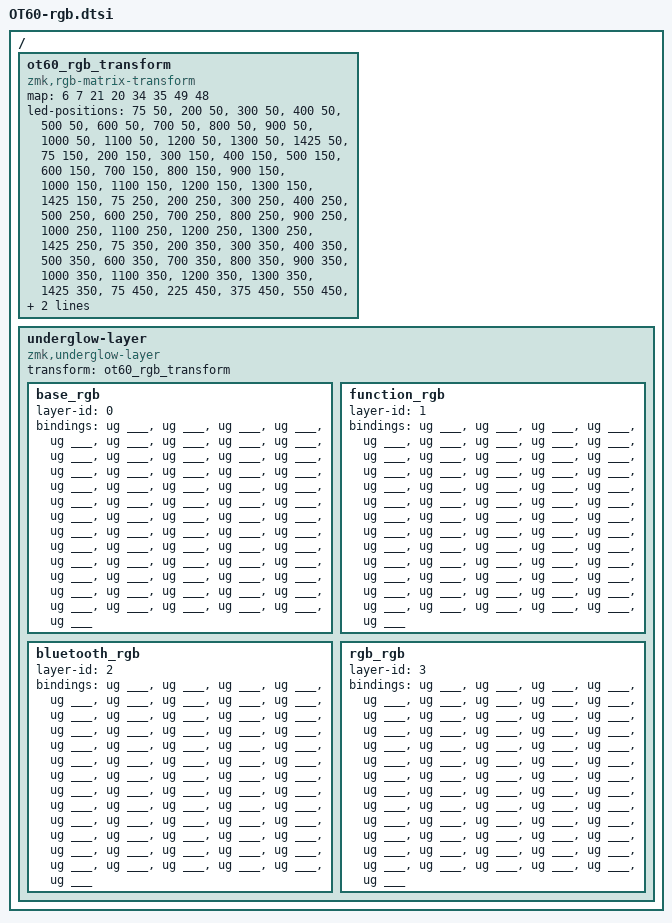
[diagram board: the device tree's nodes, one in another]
/* Copyright (c) 2026 Team PHDesign
 * SPDX-License-Identifier: MIT
 */
#include <dt-bindings/zmk/rgb_colors.h>

/ {
    ot60_rgb_transform: ot60_rgb_transform {
        compatible = "zmk,rgb-matrix-transform";
        // RGB1..RGB8 -> S7,S8,S22,S21,S35,S36,S50,S49 (PCB position export).
        map = <6 7 21 20 34 35 49 48>;
        led-positions = <75 50>
                      , <200 50>
                      , <300 50>
                      , <400 50>
                      , <500 50>
                      , <600 50>
                      , <700 50>
                      , <800 50>
                      , <900 50>
                      , <1000 50>
                      , <1100 50>
                      , <1200 50>
                      , <1300 50>
                      , <1425 50>
                      , <75 150>
                      , <200 150>
                      , <300 150>
                      , <400 150>
                      , <500 150>
                      , <600 150>
                      , <700 150>
                      , <800 150>
                      , <900 150>
                      , <1000 150>
                      , <1100 150>
                      , <1200 150>
                      , <1300 150>
                      , <1425 150>
                      , <75 250>
                      , <200 250>
                      , <300 250>
                      , <400 250>
                      , <500 250>
                      , <600 250>
                      , <700 250>
                      , <800 250>
                      , <900 250>
                      , <1000 250>
                      , <1100 250>
                      , <1200 250>
                      , <1300 250>
                      , <1425 250>
                      , <75 350>
                      , <200 350>
                      , <300 350>
                      , <400 350>
                      , <500 350>
                      , <600 350>
                      , <700 350>
                      , <800 350>
                      , <900 350>
                      , <1000 350>
                      , <1100 350>
                      , <1200 350>
                      , <1300 350>
                      , <1425 350>
                      , <75 450>
                      , <225 450>
                      , <375 450>
                      , <550 450>
                      , <750 450>
                      , <950 450>
                      , <1125 450>
                      , <1275 450>
                      , <1425 450>;
    };
    underglow-layer {
        compatible = "zmk,underglow-layer";
        transform = <&ot60_rgb_transform>;
        base_rgb {
            layer-id = <0>;
            bindings = <
                &ug ___ &ug ___ &ug ___ &ug ___ &ug ___ &ug ___ &ug ___ &ug ___ &ug ___ &ug ___ &ug ___ &ug ___ &ug ___ &ug ___
                &ug ___ &ug ___ &ug ___ &ug ___ &ug ___ &ug ___ &ug ___ &ug ___ &ug ___ &ug ___ &ug ___ &ug ___ &ug ___ &ug ___
                &ug ___ &ug ___ &ug ___ &ug ___ &ug ___ &ug ___ &ug ___ &ug ___ &ug ___ &ug ___ &ug ___ &ug ___ &ug ___ &ug ___
                &ug ___ &ug ___ &ug ___ &ug ___ &ug ___ &ug ___ &ug ___ &ug ___ &ug ___ &ug ___ &ug ___ &ug ___ &ug ___ &ug ___
                &ug ___ &ug ___ &ug ___ &ug ___ &ug ___ &ug ___ &ug ___ &ug ___ &ug ___
            >;
        };
        function_rgb {
            layer-id = <1>;
            bindings = <
                &ug ___ &ug ___ &ug ___ &ug ___ &ug ___ &ug ___ &ug ___ &ug ___ &ug ___ &ug ___ &ug ___ &ug ___ &ug ___ &ug ___
                &ug ___ &ug ___ &ug ___ &ug ___ &ug ___ &ug ___ &ug ___ &ug ___ &ug ___ &ug ___ &ug ___ &ug ___ &ug ___ &ug ___
                &ug ___ &ug ___ &ug ___ &ug ___ &ug ___ &ug ___ &ug ___ &ug ___ &ug ___ &ug ___ &ug ___ &ug ___ &ug ___ &ug ___
                &ug ___ &ug ___ &ug ___ &ug ___ &ug ___ &ug ___ &ug ___ &ug ___ &ug ___ &ug ___ &ug ___ &ug ___ &ug ___ &ug ___
                &ug ___ &ug ___ &ug ___ &ug ___ &ug ___ &ug ___ &ug ___ &ug ___ &ug ___
            >;
        };
        bluetooth_rgb {
            layer-id = <2>;
            bindings = <
                &ug ___ &ug ___ &ug ___ &ug ___ &ug ___ &ug ___ &ug ___ &ug ___ &ug ___ &ug ___ &ug ___ &ug ___ &ug ___ &ug ___
                &ug ___ &ug ___ &ug ___ &ug ___ &ug ___ &ug ___ &ug ___ &ug ___ &ug ___ &ug ___ &ug ___ &ug ___ &ug ___ &ug ___
                &ug ___ &ug ___ &ug ___ &ug ___ &ug ___ &ug ___ &ug ___ &ug ___ &ug ___ &ug ___ &ug ___ &ug ___ &ug ___ &ug ___
                &ug ___ &ug ___ &ug ___ &ug ___ &ug ___ &ug ___ &ug ___ &ug ___ &ug ___ &ug ___ &ug ___ &ug ___ &ug ___ &ug ___
                &ug ___ &ug ___ &ug ___ &ug ___ &ug ___ &ug ___ &ug ___ &ug ___ &ug ___
            >;
        };
        rgb_rgb {
            layer-id = <3>;
            bindings = <
                &ug ___ &ug ___ &ug ___ &ug ___ &ug ___ &ug ___ &ug ___ &ug ___ &ug ___ &ug ___ &ug ___ &ug ___ &ug ___ &ug ___
                &ug ___ &ug ___ &ug ___ &ug ___ &ug ___ &ug ___ &ug ___ &ug ___ &ug ___ &ug ___ &ug ___ &ug ___ &ug ___ &ug ___
                &ug ___ &ug ___ &ug ___ &ug ___ &ug ___ &ug ___ &ug ___ &ug ___ &ug ___ &ug ___ &ug ___ &ug ___ &ug ___ &ug ___
                &ug ___ &ug ___ &ug ___ &ug ___ &ug ___ &ug ___ &ug ___ &ug ___ &ug ___ &ug ___ &ug ___ &ug ___ &ug ___ &ug ___
                &ug ___ &ug ___ &ug ___ &ug ___ &ug ___ &ug ___ &ug ___ &ug ___ &ug ___
            >;
        };
    };
};
